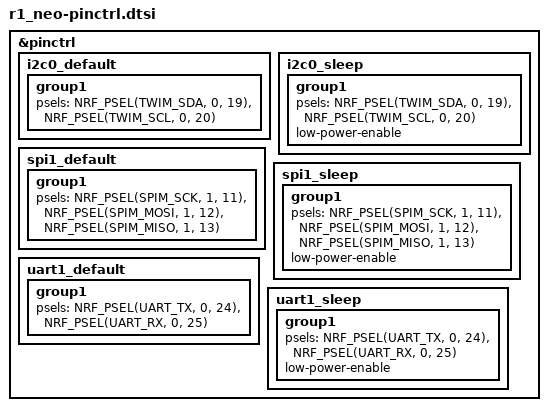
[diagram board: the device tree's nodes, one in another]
/*
 * SPDX-License-Identifier: GPL-3.0-or-later
 * SPDX-FileCopyrightText: The contributors to the LICHEN project
 *
 * Muzi Works R1 Neo pin assignments sourced from the hardware fact Bead.
 */

&pinctrl {
	/* I2C0: RX8130CE RTC footprint, SDA=P0.19, SCL=P0.20. */
	i2c0_default: i2c0_default {
		group1 {
			psels = <NRF_PSEL(TWIM_SDA, 0, 19)>,
				<NRF_PSEL(TWIM_SCL, 0, 20)>;
		};
	};
	i2c0_sleep: i2c0_sleep {
		group1 {
			psels = <NRF_PSEL(TWIM_SDA, 0, 19)>,
				<NRF_PSEL(TWIM_SCL, 0, 20)>;
			low-power-enable;
		};
	};

	/*
	 * SPI1: SX1262 LoRa radio
	 *   SCK=P1.11  MOSI=P1.12  MISO=P1.13  CS=P1.10
	 */
	spi1_default: spi1_default {
		group1 {
			psels = <NRF_PSEL(SPIM_SCK,  1, 11)>,
				<NRF_PSEL(SPIM_MOSI, 1, 12)>,
				<NRF_PSEL(SPIM_MISO, 1, 13)>;
		};
	};
	spi1_sleep: spi1_sleep {
		group1 {
			psels = <NRF_PSEL(SPIM_SCK,  1, 11)>,
				<NRF_PSEL(SPIM_MOSI, 1, 12)>,
				<NRF_PSEL(SPIM_MISO, 1, 13)>;
			low-power-enable;
		};
	};

	/*
	 * UART1: GNSS UART pins. Meshtastic and MeshCore disagree on RX/TX
	 * naming, so the UART remains disabled until hardware validation.
	 */
	uart1_default: uart1_default {
		group1 {
			psels = <NRF_PSEL(UART_TX, 0, 24)>,
				<NRF_PSEL(UART_RX, 0, 25)>;
		};
	};
	uart1_sleep: uart1_sleep {
		group1 {
			psels = <NRF_PSEL(UART_TX, 0, 24)>,
				<NRF_PSEL(UART_RX, 0, 25)>;
			low-power-enable;
		};
	};
};
